# RockChip_RK3588 register map
Vendor: RockChip Electronics Co., Ltd.; Series: RK3588; File version: 0.1
Registers are 32-bit, read-write, no defined reset value unless marked. A register's access mark holds for its fields unless they carry their own. Offsets are from the block's base; [hi:lo] are bit positions; {n}, {i} and the like mark numbered series.

## IOC_VCCIO1_4
Base 0xFD5F9000
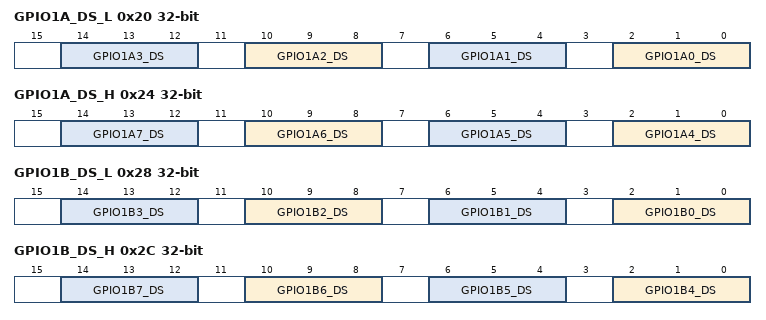
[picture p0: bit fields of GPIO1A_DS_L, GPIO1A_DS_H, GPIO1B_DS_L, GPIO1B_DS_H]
0x20 GPIO1A_DS_L — GPIO1A Driver Strength Control Low bits
  [all] fields
    0=100OHM; 4=66OHM; 2=50OHM; 6=40OHM; 1=33OHM; 5=25OHM
  [4n+2:4n] GPIO1A{n}_DS (n=0..3) — GPIO1A{n} DS control Driver Strength Selection
0x24 GPIO1A_DS_H — GPIO1A Driver Strength Control High bits
  [all] fields
    0=100OHM; 4=66OHM; 2=50OHM; 6=40OHM; 1=33OHM; 5=25OHM
  [4n-14:4n-16] GPIO1A{n}_DS (n=4..7) — GPIO1A{n} DS control Driver Strength Selection
0x28 GPIO1B_DS_L — GPIO1B Driver Strength Control Low bits
  [all] fields
    0=100OHM; 4=66OHM; 2=50OHM; 6=40OHM; 1=33OHM; 5=25OHM
  [4n+2:4n] GPIO1B{n}_DS (n=0..3) — GPIO1B{n} DS control Driver Strength Selection
0x2C GPIO1B_DS_H — GPIO1B Driver Strength Control High bits
  [all] fields
    0=100OHM; 4=66OHM; 2=50OHM; 6=40OHM; 1=33OHM; 5=25OHM
  [4n-14:4n-16] GPIO1B{n}_DS (n=4..7) — GPIO1D{n} DS control Driver Strength Selection
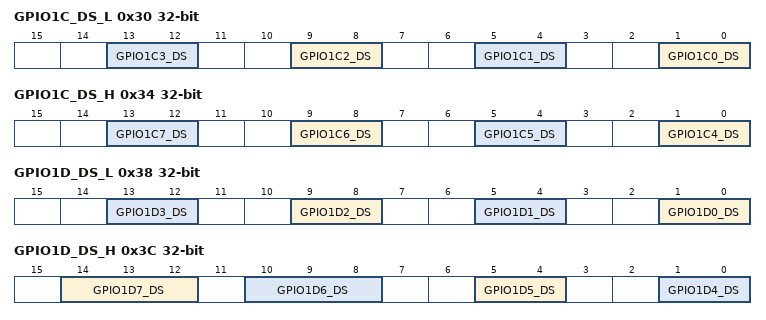
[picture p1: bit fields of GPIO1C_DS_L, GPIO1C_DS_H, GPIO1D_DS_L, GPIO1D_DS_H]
0x30 GPIO1C_DS_L — GPIO1C Driver Strength Control Low bits
  [all] fields
    0=2_5MA_100OHM; 2=5MA_50OHM; 1=7_5MA_33OHM; 3=10MA_25OHM
  [4n+1:4n] GPIO1C{n}_DS (n=0..3) — GPIO1C{n} DS control Driver Strength Selection
0x34 GPIO1C_DS_H — GPIO1C Driver Strength Control High bits
  [all] fields
    0=2_5MA_100OHM; 2=5MA_50OHM; 1=7_5MA_33OHM; 3=10MA_25OHM
  [4n-15:4n-16] GPIO1C{n}_DS (n=4..7) — GPIO1C{n} DS control Driver Strength Selection
0x38 GPIO1D_DS_L — GPIO1D Driver Strength Control Low bits
  [all] fields
    0=2_5MA_100OHM; 2=5MA_50OHM; 1=7_5MA_33OHM; 3=10MA_25OHM
  [4n+1:4n] GPIO1D{n}_DS (n=0..3) — GPIO1D{n} DS control Driver Strength Selection
0x3C GPIO1D_DS_H — GPIO1D Driver Strength Control High bits
  [14:12] GPIO1D7_DS — GPIO1D7 DS control Driver Strength Selection
    0=100OHM; 4=66OHM; 2=50OHM; 6=40OHM; 1=33OHM; 5=25OHM
  [10:8] GPIO1D6_DS — GPIO1D6 DS control Driver Strength Selection
    0=100OHM; 4=66OHM; 2=50OHM; 6=40OHM; 1=33OHM; 5=25OHM
  [5:4] GPIO1D5_DS — GPIO1D5 DS control Driver Strength Selection
    0=2_5MA_100OHM; 2=5MA_50OHM; 1=7_5MA_33OHM; 3=10MA_25OHM
  [1:0] GPIO1D4_DS — GPIO1D4 DS control Driver Strength Selection
    0=2_5MA_100OHM; 2=5MA_50OHM; 1=7_5MA_33OHM; 3=10MA_25OHM
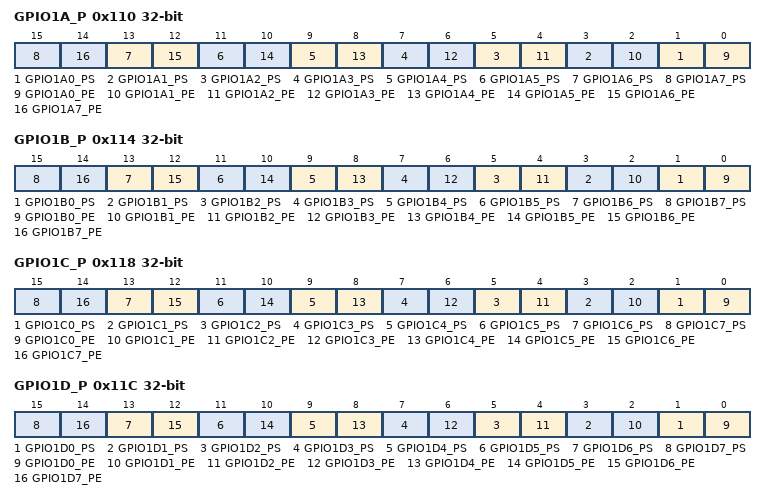
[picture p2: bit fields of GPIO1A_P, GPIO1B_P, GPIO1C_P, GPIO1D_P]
0x110 GPIO1A_P — GPIO1A Pull-up/down Control
  [2n+1] GPIO1A{n}_PS (n=0..7) — GPIO1A{n} PS control Weak PU/PD Resistor Selection
    0=PD_SELECTION; 1=PU_SELECTION
  [2n] GPIO1A{n}_PE (n=0..7) — GPIO1A{n} PE control Active High Weak PU/PD Resistor Enable
    0=PU_PD_DISABLE; 1=PU_PD_ENABLE
0x114 GPIO1B_P — GPIO1B Pull-up/down Control
  [2n+1] GPIO1B{n}_PS (n=0..7) — GPIO1B{n} PS control Weak PU/PD Resistor Selection
    0=PD_SELECTION; 1=PU_SELECTION
  [2n] GPIO1B{n}_PE (n=0..7) — GPIO1B{n} PE control Active High Weak PU/PD Resistor Enable
    0=PU_PD_DISABLE; 1=PU_PD_ENABLE
0x118 GPIO1C_P — GPIO1C Pull-up/down Control
  [2n+1] GPIO1C{n}_PS (n=0..7) — GPIO1C{n} PS control Weak PU/PD Resistor Selection
    0=PD_SELECTION; 1=PU_SELECTION
  [2n] GPIO1C{n}_PE (n=0..7) — GPIO1C{n} PE control Active High Weak PU/PD Resistor Enable
    0=PU_PD_DISABLE; 1=PU_PD_ENABLE
0x11C GPIO1D_P — GPIO1D Pull-up/down Control
  [2n+1] GPIO1D{n}_PS (n=0..7) — GPIO1D{n} PS control Weak PU/PD Resistor Selection
    0=PD_SELECTION; 1=PU_SELECTION
  [2n] GPIO1D{n}_PE (n=0..7) — GPIO1D{n} PE control Active High Weak PU/PD Resistor Enable
    0=PU_PD_DISABLE; 1=PU_PD_ENABLE
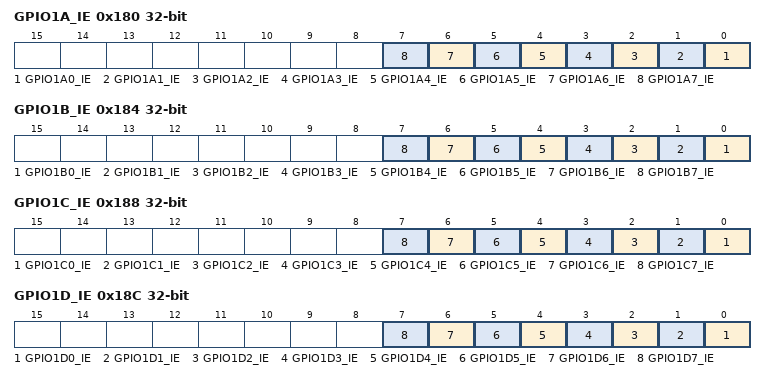
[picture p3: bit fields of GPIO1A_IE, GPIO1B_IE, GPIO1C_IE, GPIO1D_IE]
0x180 GPIO1A_IE — GPIO1A Input Enable Control
  [all] fields
    1=ENABLE; 0=DISABLE
  [n] GPIO1A{n}_IE (n=0..7) — GPIO1A{n} IE control Active High input buffer enable
0x184 GPIO1B_IE — GPIO1B Input Enable Control
  [all] fields
    1=ENABLE; 0=DISABLE
  [n] GPIO1B{n}_IE (n=0..7) — GPIO1B{n} IE control Active High input buffer enable
0x188 GPIO1C_IE — GPIO1C Input Enable Control
  [all] fields
    1=ENABLE; 0=DISABLE
  [n] GPIO1C{n}_IE (n=0..7) — GPIO1C{n} IE control Active High input buffer enable
0x18C GPIO1D_IE — GPIO1D Input Enable Control
  [all] fields
    1=ENABLE; 0=DISABLE
  [n] GPIO1D{n}_IE (n=0..7) — GPIO1D{n} IE control Active High input buffer enable
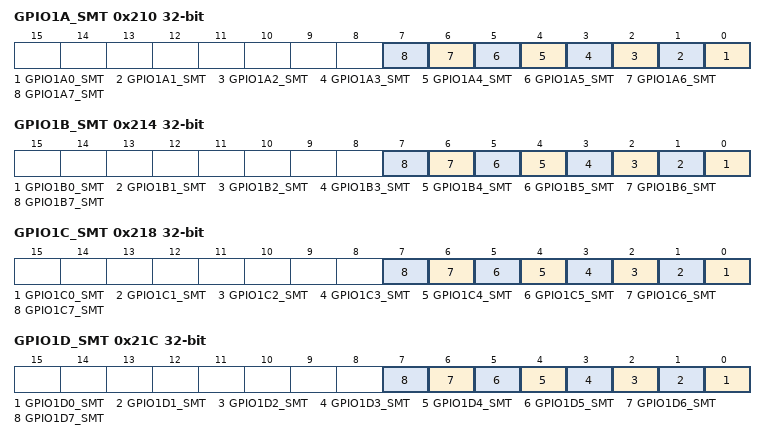
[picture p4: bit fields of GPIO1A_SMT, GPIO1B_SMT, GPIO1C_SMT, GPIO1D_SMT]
0x210 GPIO1A_SMT — GPIO1A Schmitt Trigger Control
  [all] fields
    0=CMOS; 1=SCHMITT_TRIGGER
  [n] GPIO1A{n}_SMT (n=0..7) — GPIO1A{n} SMT control CMOS/Schmitt Trigger Selection
0x214 GPIO1B_SMT — GPIO1B Schmitt Trigger Control
  [all] fields
    0=CMOS; 1=SCHMITT_TRIGGER
  [n] GPIO1B{n}_SMT (n=0..7) — GPIO1B{n} SMT control CMOS/Schmitt Trigger Selection
0x218 GPIO1C_SMT — GPIO1C Schmitt Trigger Control
  [all] fields
    0=CMOS; 1=SCHMITT_TRIGGER
  [n] GPIO1C{n}_SMT (n=0..7) — GPIO1C{n} SMT control CMOS/Schmitt Trigger Selection
0x21C GPIO1D_SMT — GPIO1D Schmitt Trigger Control
  [all] fields
    0=CMOS; 1=SCHMITT_TRIGGER
  [n] GPIO1D{n}_SMT (n=0..7) — GPIO1D{n} SMT control CMOS/Schmitt Trigger Selection
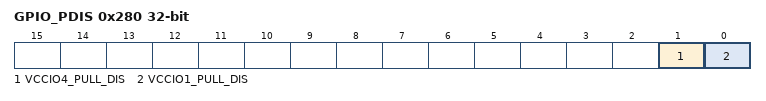
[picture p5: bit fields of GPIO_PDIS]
0x280 GPIO_PDIS — Auto Pull-up/down disable Control
  [1] VCCIO4_PULL_DIS
    1=DISABLE (disable VCCIO4 GPIO pull up/down when output enable)
  [0] VCCIO1_PULL_DIS
    1=DISABLE (disable VCCIO1 GPIO pull up/down when output enable)
